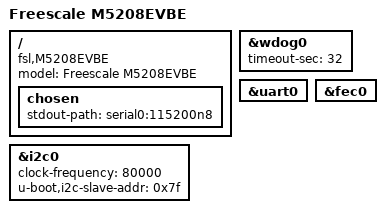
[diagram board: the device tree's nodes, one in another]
// SPDX-License-Identifier: GPL-2.0+
/*
 * Copyright (C) 2018 Angelo Dureghello <angelo@sysam.it>
 */

/dts-v1/;
/include/ "mcf5208.dtsi"

/ {
	model = "Freescale M5208EVBE";
	compatible = "fsl,M5208EVBE";

	chosen {
		stdout-path = "serial0:115200n8";
	};
};

&wdog0 {
	timeout-sec = <32>;
	status = "okay";
};

&uart0 {
	bootph-all;
	status = "okay";
};

&fec0 {
	status = "okay";
};

&i2c0 {
	clock-frequency = <80000>;
	u-boot,i2c-slave-addr = <0x7f>;
	status = "okay";
};
